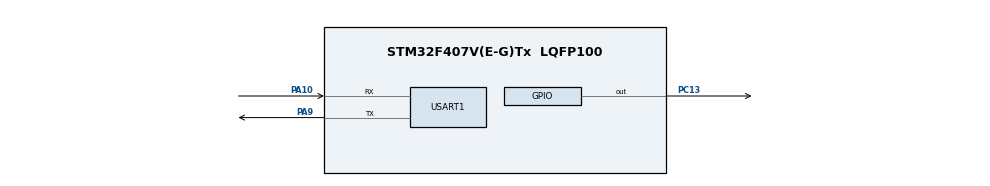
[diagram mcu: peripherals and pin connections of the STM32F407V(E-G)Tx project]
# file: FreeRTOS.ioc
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FREERTOS.Tasks01=defaultTask,24,128,StartDefaultTask,Default,NULL,Dynamic,NULL,NULL
Mcu.Family=STM32F4
Mcu.Name=STM32F407V(E-G)Tx
Mcu.Package=LQFP100
NVIC.PriorityGroup=NVIC_PRIORITYGROUP_4
NVIC.TIM4_IRQn=true\:15\:0\:false\:false\:true\:false\:false\:true\:true
NVIC.TimeBase=TIM4_IRQn
NVIC.TimeBaseIP=TIM4
PA10.Mode=Asynchronous
PA10.Signal=USART1_RX
PA13.Mode=Serial_Wire
PA13.Signal=SYS_JTMS-SWDIO
PA14.Mode=Serial_Wire
PA14.Signal=SYS_JTCK-SWCLK
PA9.Mode=Asynchronous
PA9.Signal=USART1_TX
PC13-ANTI_TAMP.GPIO_PuPd=GPIO_PULLUP
PC13-ANTI_TAMP.Signal=GPIO_Output
PC14-OSC32_IN.Mode=LSE-External-Oscillator
PC14-OSC32_IN.Signal=RCC_OSC32_IN
PC15-OSC32_OUT.Mode=LSE-External-Oscillator
PC15-OSC32_OUT.Signal=RCC_OSC32_OUT
PH0-OSC_IN.Mode=HSE-External-Oscillator
PH0-OSC_IN.Signal=RCC_OSC_IN
PH1-OSC_OUT.Mode=HSE-External-Oscillator
PH1-OSC_OUT.Signal=RCC_OSC_OUT
ProjectManager.HeapSize=0x200
ProjectManager.StackSize=0x400
ProjectManager.TargetToolchain=MDK-ARM V5
RCC.48MHZClocksFreq_Value=84000000
RCC.AHBFreq_Value=168000000
RCC.APB1CLKDivider=RCC_HCLK_DIV4
RCC.APB1Freq_Value=42000000
RCC.APB1TimFreq_Value=84000000
RCC.APB2CLKDivider=RCC_HCLK_DIV2
RCC.APB2Freq_Value=84000000
RCC.APB2TimFreq_Value=168000000
RCC.CortexFreq_Value=168000000
RCC.HCLKFreq_Value=168000000
RCC.HSE_VALUE=25000000
RCC.HSI_VALUE=16000000
RCC.PLLM=25
RCC.PLLN=336
RCC.PLLSourceVirtual=RCC_PLLSOURCE_HSE
RCC.SYSCLKFreq_VALUE=168000000
RCC.SYSCLKSource=RCC_SYSCLKSOURCE_PLLCLK
RCC.VCOOutputFreq_Value=336000000
USART1.VirtualMode=VM_ASYNC
VP_FREERTOS_VS_CMSIS_V2.Mode=CMSIS_V2
VP_SYS_VS_tim4.Mode=TIM4
board=custom

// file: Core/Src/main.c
/* USER CODE BEGIN Header */
/**
  ******************************************************************************
  * @file           : main.c
  * @brief          : Main program body
  ******************************************************************************
  * @attention
  *
  * Copyright (c) 2024 STMicroelectronics.
  * All rights reserved.
  *
  * This software is licensed under terms that can be found in the LICENSE file
  * in the root directory of this software component.
  * If no LICENSE file comes with this software, it is provided AS-IS.
  *
  ******************************************************************************
  */
/* USER CODE END Header */
#include "main.h"
#include "cmsis_os.h"
#include "usart.h"
#include "gpio.h"

void SystemClock_Config(void);
void MX_FREERTOS_Init(void);

int main(void)
{

  /* MCU Configuration--------------------------------------------------------*/

  /* Reset of all peripherals, Initializes the Flash interface and the Systick. */
  HAL_Init();

  /* Configure the system clock */
  SystemClock_Config();

  /* Initialize all configured peripherals */
  MX_GPIO_Init();
  MX_USART1_UART_Init();

  /* Init scheduler */
  osKernelInitialize();

  /* Call init function for freertos objects (in cmsis_os2.c) */
  MX_FREERTOS_Init();

  /* Start scheduler */
  osKernelStart();

  /* We should never get here as control is now taken by the scheduler */

  /* Infinite loop */
  while (1)
  {

  }
}

void SystemClock_Config(void)
{
  LL_FLASH_SetLatency(LL_FLASH_LATENCY_5);
  while(LL_FLASH_GetLatency()!= LL_FLASH_LATENCY_5)
  {
  }
  LL_PWR_SetRegulVoltageScaling(LL_PWR_REGU_VOLTAGE_SCALE1);
  LL_RCC_HSE_Enable();

   /* Wait till HSE is ready */
  while(LL_RCC_HSE_IsReady() != 1)
  {

  }
  LL_RCC_PLL_ConfigDomain_SYS(LL_RCC_PLLSOURCE_HSE, LL_RCC_PLLM_DIV_25, 336, LL_RCC_PLLP_DIV_2);
  LL_RCC_PLL_Enable();

   /* Wait till PLL is ready */
  while(LL_RCC_PLL_IsReady() != 1)
  {

  }
  while (LL_PWR_IsActiveFlag_VOS() == 0)
  {
  }
  LL_RCC_SetAHBPrescaler(LL_RCC_SYSCLK_DIV_1);
  LL_RCC_SetAPB1Prescaler(LL_RCC_APB1_DIV_4);
  LL_RCC_SetAPB2Prescaler(LL_RCC_APB2_DIV_2);
  LL_RCC_SetSysClkSource(LL_RCC_SYS_CLKSOURCE_PLL);

   /* Wait till System clock is ready */
  while(LL_RCC_GetSysClkSource() != LL_RCC_SYS_CLKSOURCE_STATUS_PLL)
  {

  }
  LL_SetSystemCoreClock(168000000);

   /* Update the time base */
  if (HAL_InitTick (TICK_INT_PRIORITY) != HAL_OK)
  {
    Error_Handler();
  }
}

void HAL_TIM_PeriodElapsedCallback(TIM_HandleTypeDef *htim)
{
  if (htim->Instance == TIM4) {
    HAL_IncTick();
  }
}

void Error_Handler(void)
{
  __disable_irq();
  while (1)
  {
  }
}

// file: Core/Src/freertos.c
/* USER CODE BEGIN Header */
/**
 ******************************************************************************
 * File Name          : freertos.c
 * Description        : Code for freertos applications
 ******************************************************************************
 * @attention
 *
 * Copyright (c) 2024 STMicroelectronics.
 * All rights reserved.
 *
 * This software is licensed under terms that can be found in the LICENSE file
 * in the root directory of this software component.
 * If no LICENSE file comes with this software, it is provided AS-IS.
 *
 ******************************************************************************
 */
/* USER CODE END Header */

#include "FreeRTOS.h"
#include "task.h"
#include "main.h"
#include "cmsis_os.h"

/* USER CODE BEGIN Includes */
#include "stdio.h"
/* USER CODE END Includes */

/* Definitions for defaultTask */
osThreadId_t defaultTaskHandle;
const osThreadAttr_t defaultTask_attributes = {
  .name = "defaultTask",
  .stack_size = 128 * 4,
  .priority = (osPriority_t) osPriorityNormal,
};

/* USER CODE BEGIN FunctionPrototypes */
void LEDToggle_Task(void *argument)
{
  while (1)
  {
    LL_GPIO_TogglePin(GPIOC, LL_GPIO_PIN_13);
    osDelay(500);
  }
}

void SerialSend_Task(void *argument)
{
  while (1)
  {
    printf("Hello World!\r\n");
    osDelay(1000);
  }
}

/* USER CODE END FunctionPrototypes */

void StartDefaultTask(void *argument);

void MX_FREERTOS_Init(void); /* (MISRA C 2004 rule 8.1) */

void MX_FREERTOS_Init(void) {

  /* Create the thread(s) */
  /* creation of defaultTask */
  defaultTaskHandle = osThreadNew(StartDefaultTask, NULL, &defaultTask_attributes);
  /* USER CODE BEGIN RTOS_THREADS */
  /* add threads, ... */
  xTaskCreate(LEDToggle_Task, "LEDToggle_Task", 128, NULL, osPriorityNormal+1, NULL);
  xTaskCreate(SerialSend_Task, "SerialSend_Task", 128, NULL, osPriorityNormal+1, NULL);

  /* USER CODE END RTOS_THREADS */

}

void StartDefaultTask(void *argument)
{
  while (1)
  {
    /* code */
  }

  /* USER CODE BEGIN StartDefaultTask */
  /* Infinite loop */
  // for (;;)
  // {
  //   LL_GPIO_SetOutputPin(GPIOC, LL_GPIO_PIN_13);
  //   osDelay(500);
  //   LL_GPIO_ResetOutputPin(GPIOC, LL_GPIO_PIN_13);
  //   osDelay(500);
  // }
  /* USER CODE END StartDefaultTask */
}
